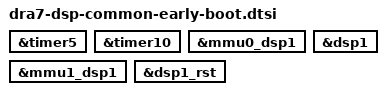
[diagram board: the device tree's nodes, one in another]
// SPDX-License-Identifier: GPL-2.0+
/*
 * Copyright (C) 2019 Texas Instruments Incorporated - http://www.ti.com/
 */

&timer5 {
	u-boot,dm-spl;
};

&timer10 {
	u-boot,dm-spl;
};

&mmu0_dsp1 {
	u-boot,dm-spl;
};

&mmu1_dsp1 {
	u-boot,dm-spl;
};

&dsp1 {
	status = "okay";
	u-boot,dm-spl;
};

&dsp1_rst {
	u-boot,dm-spl;
};

